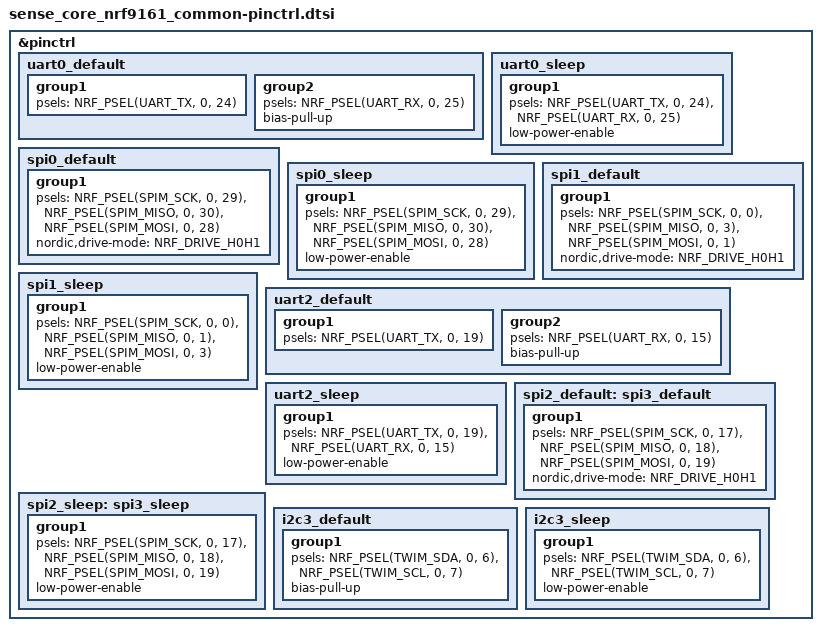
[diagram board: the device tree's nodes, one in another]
&pinctrl {
	uart0_default: uart0_default {
		group1 {
			psels = <NRF_PSEL(UART_TX, 0, 24)>;
		};
		group2 {
			psels = <NRF_PSEL(UART_RX, 0, 25)>;
			bias-pull-up;
		};
	};

	uart0_sleep: uart0_sleep {
		group1 {
			psels = <NRF_PSEL(UART_TX, 0, 24)>,
				<NRF_PSEL(UART_RX, 0, 25)>;
			low-power-enable;
		};
	};

	spi0_default: spi0_default {
		group1 {
			psels = <NRF_PSEL(SPIM_SCK, 0, 29)>,
				<NRF_PSEL(SPIM_MISO, 0, 30)>,
				<NRF_PSEL(SPIM_MOSI, 0, 28)>;
			nordic,drive-mode = <NRF_DRIVE_H0H1>;
		};
	};

	spi0_sleep: spi0_sleep {
		group1 {
			psels = <NRF_PSEL(SPIM_SCK, 0, 29)>,
				<NRF_PSEL(SPIM_MISO, 0, 30)>,
				<NRF_PSEL(SPIM_MOSI, 0, 28)>;
			low-power-enable;
		};
	};

	spi1_default: spi1_default {
		group1 {
			psels = <NRF_PSEL(SPIM_SCK, 0, 0)>,
				<NRF_PSEL(SPIM_MISO, 0, 3)>,
				<NRF_PSEL(SPIM_MOSI, 0, 1)>;
			nordic,drive-mode = <NRF_DRIVE_H0H1>;
		};
	};

	spi1_sleep: spi1_sleep {
		group1 {
			psels = <NRF_PSEL(SPIM_SCK, 0, 0)>,
				<NRF_PSEL(SPIM_MISO, 0, 1)>,
				<NRF_PSEL(SPIM_MOSI, 0, 3)>;
			low-power-enable;
		};
	};

	uart2_default: uart2_default {
		group1 {
			psels = <NRF_PSEL(UART_TX, 0, 19)>;
		};
		group2 {
			psels = <NRF_PSEL(UART_RX, 0, 15)>;
			bias-pull-up;
		};
	};

	uart2_sleep: uart2_sleep {
		group1 {
			psels = <NRF_PSEL(UART_TX, 0, 19)>,
				<NRF_PSEL(UART_RX, 0, 15)>;
			low-power-enable;
		};
	};

	spi2_default: spi3_default {
		group1 {
			psels = <NRF_PSEL(SPIM_SCK, 0, 17)>,
				<NRF_PSEL(SPIM_MISO, 0, 18)>,
				<NRF_PSEL(SPIM_MOSI, 0, 19)>;
			nordic,drive-mode = <NRF_DRIVE_H0H1>;
		};
	};

	spi2_sleep: spi3_sleep {
		group1 {
			psels = <NRF_PSEL(SPIM_SCK, 0, 17)>,
				<NRF_PSEL(SPIM_MISO, 0, 18)>,
				<NRF_PSEL(SPIM_MOSI, 0, 19)>;
			low-power-enable;
		};
	};

	i2c3_default: i2c3_default {
		group1 {
			psels = <NRF_PSEL(TWIM_SDA, 0, 6)>,
				<NRF_PSEL(TWIM_SCL, 0, 7)>;
			bias-pull-up;
		};
	};

	i2c3_sleep: i2c3_sleep {
		group1 {
			psels = <NRF_PSEL(TWIM_SDA, 0, 6)>,
				<NRF_PSEL(TWIM_SCL, 0, 7)>;
			low-power-enable;
		};
	};
};
